# ATtiny861 register map
Vendor: Atmel
Registers are 8-bit, read-write, reset 0x0 unless marked. A register's access mark holds for its fields unless they carry their own. Offsets are from the block's base; [hi:lo] are bit positions; 'fields as' and 'values as' point back to an identical list; <NAME> marks a mode.

## TC1 — Timer/Counter1, 10-bit
Base 0x00000020
0x00 TCCR1E — Timer/Counter1 Control Register E
  [5:0] OC1OE — Ouput Compare Override Enable Bits
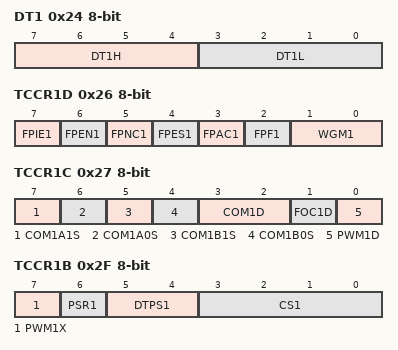
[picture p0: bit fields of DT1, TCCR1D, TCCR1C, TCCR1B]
0x24 DT1 — Timer/Counter 1 Dead Time Value
  [7:4] DT1H — <TBD>
  [3:0] DT1L — <TBD>
0x25 TC1H — Timer/Counter High Bits
0x26 TCCR1D — Timer/Counter Control Register D
  [7] FPIE1 — Fault Protection Interrupt Enable
  [6] FPEN1 — Fault Protection Mode Enable
  [5] FPNC1 — Fault Protection Noise Canceler
  [4] FPES1 — Fault Protection Edge Select
  [3] FPAC1 — Fault Protection Analog Comparator Enable
  [2] FPF1 — Fault Protection Interrupt Flag
  [1:0] WGM1 — Waveform Generation Mode Bit
    0=PWM_FAST (Fast PWM, Update: *TOP*, Flag: *TOP*); 1=PWM_CORRECT (Phase and Frequency Correct PWM, Update: *BOTTOM*, Flag: *BOTTOM*); 2=PWM_SINGLE_SLOPE (PWM6 / Single-slope, Update: *TOP*, Flag: *TOP*); 3=PWM_DUAL_SLOPE (PWM6 / Dual-slope, Update: *BOTTOM*, Flag: *BOTTOM*)
0x27 TCCR1C — Timer/Counter Control Register C
  [7] COM1A1S — COM1A1 Shadow Bit
  [6] COM1A0S — COM1A0 Shadow Bit
  [5] COM1B1S — COM1B1 Shadow Bit
  [4] COM1B0S — COM1B0 Shadow Bit
  [3:2] COM1D — Comparator D output mode
    0=DISCONNECTED (Normal port operation, OCix disconnected); 1=MATCH_TOGGLE (Toggle OCix on Compare Match (Might depend on WGM)); 2=MATCH_CLEAR (Clear OCix on Compare Match (If PWM is enabled, OCix is set at TOP)); 3=MATCH_SET (Set OCix on Compare Match (If PWM is enabled, OCix is cleared at TOP))
  [1] FOC1D wo — Force Output Compare Match 1D
  [0] PWM1D — Pulse Width Modulator D Enable
0x2A OCR1D ro — Output compare register
0x2B OCR1C — Output compare register
0x2C OCR1B — Output Compare Register
0x2D OCR1A — Output Compare Register
0x2E TCNT1 ro — Timer/Counter Register
0x2F TCCR1B — Timer/Counter Control Register B
  [7] PWM1X — PWM Inversion Mode
  [6] PSR1 — Timer/Counter 1 Prescaler reset
  [5:4] DTPS1 — Dead Time Prescaler
    0=1x (no division); 1=X2 (2x); 2=X4 (4x); 3=X8 (8x)
  [3:0] CS1 — Clock Select Bits
    0=NO_CLOCK (No clock source (Timer/Counter stopped)); 1=DIRECT (Running, No Prescaling); 2=PRESCALE_2 (Running, CLK/2); 3=PRESCALE_4 (Running, CLK/4); 4=PRESCALE_8 (Running, CLK/8); 5=PRESCALE_16 (Running, CLK/16); 6=PRESCALE_32 (Running, CLK/32); 7=PRESCALE_64 (Running, CLK/64); 8=PRESCALE_128 (Running, CLK/128); 9=PRESCALE_256 (Running, CLK/256); 10=PRESCALE_512 (Running, CLK/512); 11=PRESCALE_1024 (Running, CLK/1024); 12=PRESCALE_2048 (Running, CLK/2048); 13=PRESCALE_4096 (Running, CLK/4096); 14=PRESCALE_8192 (Running, CLK/8192); 15=PRESCALE_16384 (Running, CLK/16384)
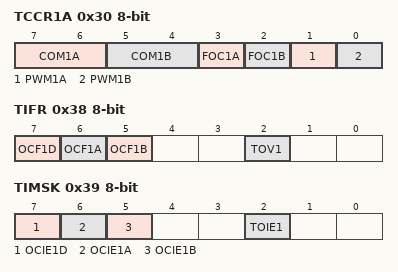
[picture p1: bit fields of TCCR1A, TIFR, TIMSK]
0x30 TCCR1A — Timer/Counter Control Register A
  [7:6] COM1A — Compare Output Mode, Bits
    values as TCCR1C.COM1D
  [5:4] COM1B — Compare Output Mode, Bits
    values as TCCR1C.COM1D
  [3] FOC1A wo — Force Output Compare Match 1A
  [2] FOC1B wo — Force Output Compare Match 1B
  [1] PWM1A — Pulse Width Modulator Enable
  [0] PWM1B — Pulse Width Modulator Enable
0x38 TIFR ro — Timer/Counter Interrupt Flag Register
  [7] OCF1D — Timer/Counter1 Output Compare Flag 1D
  [6] OCF1A — Timer/Counter1 Output Compare Flag 1A
  [5] OCF1B — Timer/Counter1 Output Compare Flag 1B
  [2] TOV1 — Timer/Counter1 Overflow Flag
0x39 TIMSK — Timer/Counter Interrupt Mask Register
  [7] OCIE1D — OCIE1D: Timer/Counter1 Output Compare Interrupt Enable
  [6] OCIE1A — OCIE1A: Timer/Counter1 Output Compare Interrupt Enable
  [5] OCIE1B — OCIE1A: Timer/Counter1 Output Compare B Interrupt Enable
  [2] TOIE1 — Timer/Counter1 Overflow Interrupt Enable

## USI — Universal Serial Interface
Base 0x0000002D
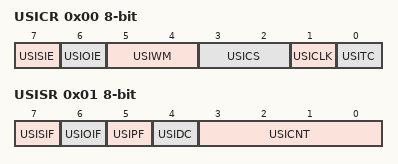
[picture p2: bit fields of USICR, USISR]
0x00 USICR — USI Control Register
  [7] USISIE — Start Condition Interrupt Enable
  [6] USIOIE — Counter Overflow Interrupt Enable
  [5:4] USIWM — USI Wire Mode Bits
    0=DISABLED (All detectors disabled. Port pins operates as normal.); 1=THREE_WIRE (Three-wire mode. Uses DO, DI, and USCK pins.); 2=TWO_WIRE_SLAVE (Two-wire mode (Slave). Uses SDA (DI) and SCL (USCK) pins.); 3=TWO_WIRE_MASTER (Two-wire mode (Master). Uses SDA and SCL pins.)
  [3:2] USICS — USI Clock Source Select Bits
    0=NO_CLOCK (No Clock/Software clock strobe); 1=TC0 (Timer/Counter0 Compare Match); 2=EXT_POS (External, positive edge); 3=EXT_NEG (External, negative edge)
  [1] USICLK wo — Clock Strobe
  [0] USITC wo — Toggle Clock Port Pin
0x01 USISR — USI Status Register
  [7] USISIF — Start Condition Interrupt Flag
  [6] USIOIF — Counter Overflow Interrupt Flag
  [5] USIPF — Stop Condition Flag
  [4] USIDC ro — Data Output Collision
  [3:0] USICNT — USI Counter Value Bits
0x02 USIDR — USI Data Register
0x03 USIBR ro — USI Buffer Register
0x04 USIPP — USI Pin Position

## WDT — Watchdog Timer
Base 0x00000041
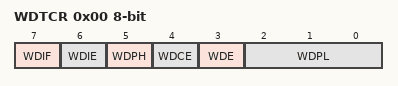
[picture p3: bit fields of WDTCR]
0x00 WDTCR — Watchdog Timer Control Register
  [7] WDIF — Watchdog Timeout Interrupt Flag
  [6] WDIE — Watchdog Timeout Interrupt Enable
  [5] WDPH — Watchdog Timer Prescaler - High Bit
  [4] WDCE — Watchdog Change Enable
  [3] WDE — Watch Dog Enable
  [2:0] WDPL — Watchdog Timer Prescaler - Low Bits
    0=CYCLES_2K_512K (- 2048 cycles, ~16ms/512K (524288) cycles, ~4s if WDPH is set); 1=CYCLES_4K_1024K (- 4096 cycles, ~32ms/1024K (1048576) cycles, ~8s if WDPH is set); 2=CYCLES_8K (- 8192 cycles, ~64ms); 3=CYCLES_16K (- 16K (16384) cycles, ~0.125s); 4=CYCLES_32K (- 32K (32768) cycles, ~0.25s); 5=CYCLES_64K (- 64K (65536) cycles, ~0.5s); 6=CYCLES_128K (- 128K (131072) cycles, ~1s); 7=CYCLES_256K (- 256K (262144) cycles, ~2s)
